# CFGAP register map
Vendor: Texas Instruments
Peripheral module from a debugger description file (folder AP).
Registers are 32-bit, read-only, reset 0x0 unless marked. A register's access mark holds for its fields unless they carry their own. Offsets are as the file gives them; lines under a group give offsets from that group; [hi:lo] are bit positions; {n}, {i} and the like mark numbered series; 'fields as' and 'values as' point back to an identical list; <NAME> marks a mode.

## Hidden
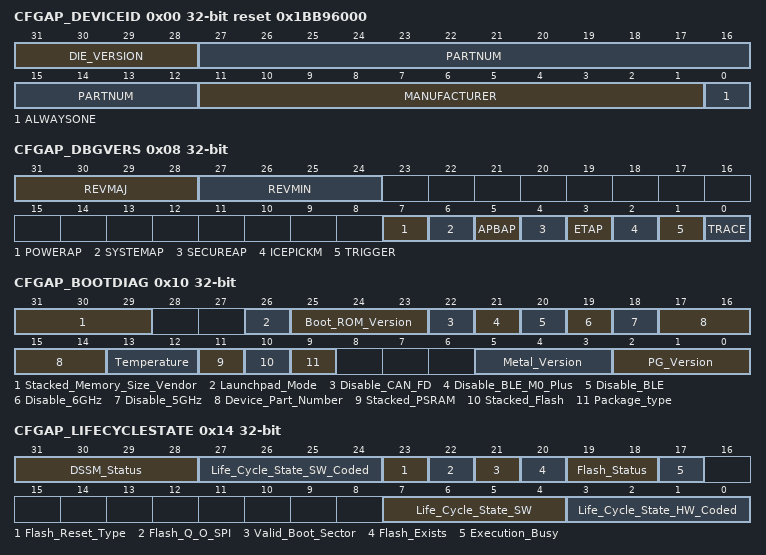
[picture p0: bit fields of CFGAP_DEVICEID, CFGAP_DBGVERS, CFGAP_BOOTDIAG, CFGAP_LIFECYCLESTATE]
0x00 CFGAP_DEVICEID reset 0x1BB96000
  [31:28] DIE_VERSION, [27:12] PARTNUM, [11:1] MANUFACTURER, [0] ALWAYSONE
0x04 CFGAP_USERCODE
  [31:0] FAULT_MARKED_LOCATION
0x08 CFGAP_DBGVERS
  [31:28] REVMAJ, [27:24] REVMIN, [7] POWERAP, [6] SYSTEMAP, [5] APBAP, [4] SECUREAP, [3] ETAP, [2] ICEPICKM, [1] TRIGGER, [0] TRACE
0x0C CFGAP_SYSSTATCTRL
  [2] STBYDIS
0x10 CFGAP_BOOTDIAG
  [31:29] Stacked_Memory_Size_Vendor, [26] Launchpad_Mode, [25:23] Boot_ROM_Version, [22] Disable_CAN_FD, [21] Disable_BLE_M0_Plus, [20] Disable_BLE, [19] Disable_6GHz, [18] Disable_5GHz, [17:14] Device_Part_Number, [13:12] Temperature, [11] Stacked_PSRAM, [10] Stacked_Flash, [9] Package_type, [5:3] Metal_Version, [2:0] PG_Version
0x14 CFGAP_LIFECYCLESTATE
  [31:28] DSSM_Status, [27:24] Life_Cycle_State_SW_Coded, [23] Flash_Reset_Type, [22] Flash_Q_O_SPI, [21] Valid_Boot_Sector, [20] Flash_Exists, [19:18] Flash_Status, [17] Execution_Busy, [7:4] Life_Cycle_State_SW, [3:0] Life_Cycle_State_HW_Coded
0x18 CFGAP_DFTEN access per field
  [0] DFTEN rw
0x1C CFGAP_RESET_REQ access per field
  [0] Reset_Req rw
0x28 CFGAP_UNIQUE_DEVICEID0
  [31:0] CFGAP_UNIQUE_DEVICEID_VALUE_LOW
0x2C CFGAP_UNIQUE_DEVICEID1
  [31:0] CFGAP_UNIQUE_DEVICEID_VALUE_HIGH
